# VPAC_DRU_UTC_VPAC0_DRU_MMR_CFG_DRU_DRU_CHATOMIC_DEBUG register map
Vendor: Texas Instruments
Peripheral module from a debugger description file (folder am62A).
Registers are 64-bit, read-only, reset 0x0 unless marked. A register's access mark holds for its fields unless they carry their own. Offsets are as the file gives them; lines under a group give offsets from that group; [hi:lo] are bit positions; {n}, {i} and the like mark numbered series; 'fields as' and 'values as' point back to an identical list; <NAME> marks a mode.

## VPAC_DRU_UTC_VPAC0_DRU_MMR_CFG_DRU_DRU_CHATOMIC_DEBUG
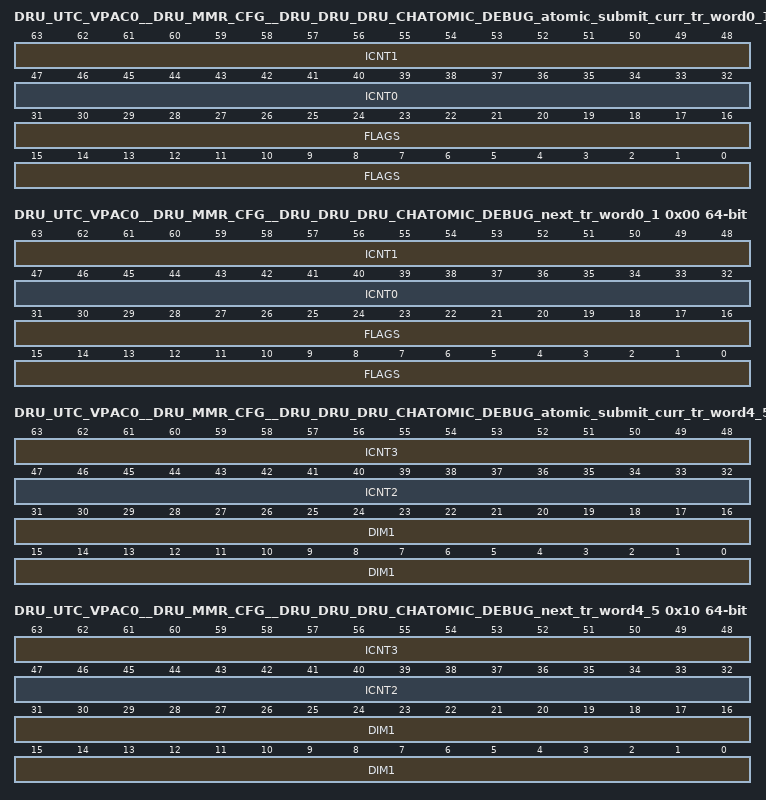
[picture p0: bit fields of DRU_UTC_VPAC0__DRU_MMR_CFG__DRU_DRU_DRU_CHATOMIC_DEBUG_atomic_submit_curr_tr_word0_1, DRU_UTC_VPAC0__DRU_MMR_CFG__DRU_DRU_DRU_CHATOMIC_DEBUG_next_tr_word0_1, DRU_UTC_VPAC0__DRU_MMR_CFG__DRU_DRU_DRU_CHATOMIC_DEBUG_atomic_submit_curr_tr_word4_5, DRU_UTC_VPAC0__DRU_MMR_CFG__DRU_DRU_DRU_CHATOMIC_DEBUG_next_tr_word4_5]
0x00 DRU_UTC_VPAC0__DRU_MMR_CFG__DRU_DRU_DRU_CHATOMIC_DEBUG_atomic_submit_curr_tr_word0_1
  [63:48] ICNT1 — Lines in a transfer
  [47:32] ICNT0 — Bytes in a transfer
  [31:0] FLAGS — Flags for the operation and type of descriptor
0x00 DRU_UTC_VPAC0__DRU_MMR_CFG__DRU_DRU_DRU_CHATOMIC_DEBUG_next_tr_word0_1
  fields as DRU_UTC_VPAC0__DRU_MMR_CFG__DRU_DRU_DRU_CHATOMIC_DEBUG_atomic_submit_curr_tr_word0_1
0x08 DRU_UTC_VPAC0__DRU_MMR_CFG__DRU_DRU_DRU_CHATOMIC_DEBUG_atomic_submit_curr_tr_word2_3
  [47:0] SRC_ADDR — Source transfer address virtual or physical allowed
0x08 DRU_UTC_VPAC0__DRU_MMR_CFG__DRU_DRU_DRU_CHATOMIC_DEBUG_next_tr_word2_3
  fields as DRU_UTC_VPAC0__DRU_MMR_CFG__DRU_DRU_DRU_CHATOMIC_DEBUG_atomic_submit_curr_tr_word2_3
0x10 DRU_UTC_VPAC0__DRU_MMR_CFG__DRU_DRU_DRU_CHATOMIC_DEBUG_atomic_submit_curr_tr_word4_5
  [63:48] ICNT3 — The size of the 4th loop in the TR transfer
  [47:32] ICNT2 — The size of the 3rd loop in the TR transfer
  [31:0] DIM1 — The first dimension width of the source data
0x10 DRU_UTC_VPAC0__DRU_MMR_CFG__DRU_DRU_DRU_CHATOMIC_DEBUG_next_tr_word4_5
  fields as DRU_UTC_VPAC0__DRU_MMR_CFG__DRU_DRU_DRU_CHATOMIC_DEBUG_atomic_submit_curr_tr_word4_5
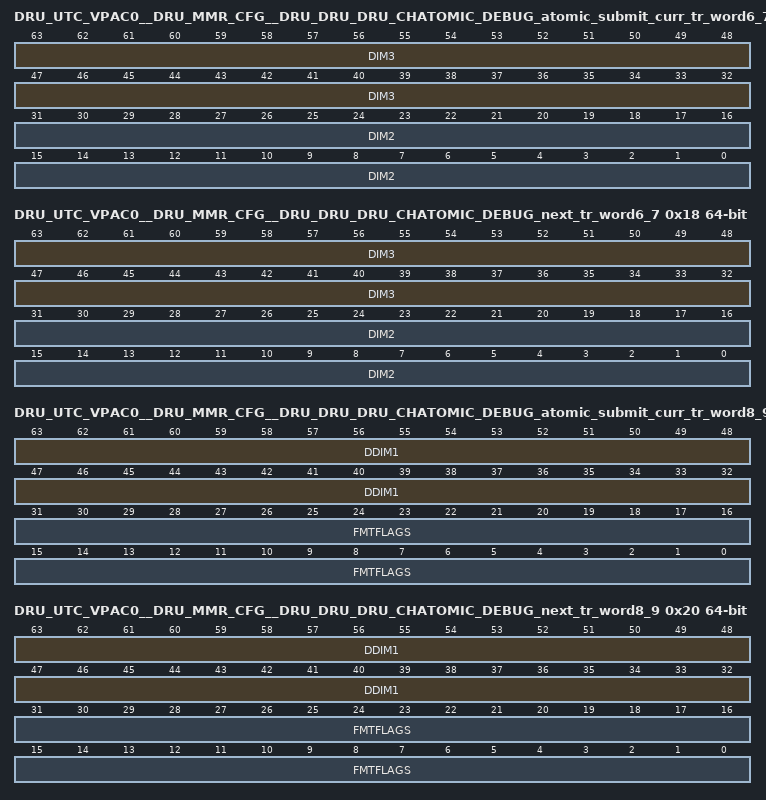
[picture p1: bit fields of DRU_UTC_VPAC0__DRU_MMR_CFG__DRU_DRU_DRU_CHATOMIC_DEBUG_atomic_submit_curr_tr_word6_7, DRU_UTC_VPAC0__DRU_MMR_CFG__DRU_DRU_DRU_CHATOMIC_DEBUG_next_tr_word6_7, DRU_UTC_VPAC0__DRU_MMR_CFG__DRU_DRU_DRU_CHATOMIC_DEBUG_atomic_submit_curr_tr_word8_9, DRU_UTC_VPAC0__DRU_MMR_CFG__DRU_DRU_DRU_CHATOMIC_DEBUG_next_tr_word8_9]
0x18 DRU_UTC_VPAC0__DRU_MMR_CFG__DRU_DRU_DRU_CHATOMIC_DEBUG_atomic_submit_curr_tr_word6_7
  [63:32] DIM3 — The third dimension width of the source data
  [31:0] DIM2 — The second dimension width of the source data
0x18 DRU_UTC_VPAC0__DRU_MMR_CFG__DRU_DRU_DRU_CHATOMIC_DEBUG_next_tr_word6_7
  fields as DRU_UTC_VPAC0__DRU_MMR_CFG__DRU_DRU_DRU_CHATOMIC_DEBUG_atomic_submit_curr_tr_word6_7
0x20 DRU_UTC_VPAC0__DRU_MMR_CFG__DRU_DRU_DRU_CHATOMIC_DEBUG_atomic_submit_curr_tr_word8_9
  [63:32] DDIM1 — The first dimension width of the destination data
  [31:0] FMTFLAGS — The data formatting flags to be used for the TR
0x20 DRU_UTC_VPAC0__DRU_MMR_CFG__DRU_DRU_DRU_CHATOMIC_DEBUG_next_tr_word8_9
  fields as DRU_UTC_VPAC0__DRU_MMR_CFG__DRU_DRU_DRU_CHATOMIC_DEBUG_atomic_submit_curr_tr_word8_9
0x28 DRU_UTC_VPAC0__DRU_MMR_CFG__DRU_DRU_DRU_CHATOMIC_DEBUG_atomic_submit_curr_tr_word10_11
  [47:0] DADDR — Destination transfer address virtual or physical allowed
0x28 DRU_UTC_VPAC0__DRU_MMR_CFG__DRU_DRU_DRU_CHATOMIC_DEBUG_next_tr_word10_11
  fields as DRU_UTC_VPAC0__DRU_MMR_CFG__DRU_DRU_DRU_CHATOMIC_DEBUG_atomic_submit_curr_tr_word10_11
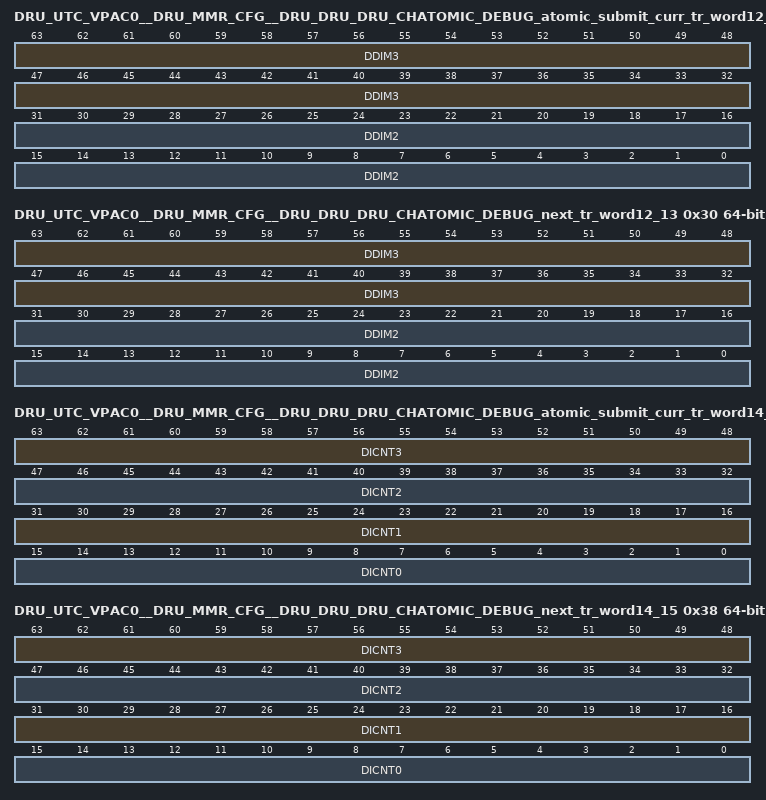
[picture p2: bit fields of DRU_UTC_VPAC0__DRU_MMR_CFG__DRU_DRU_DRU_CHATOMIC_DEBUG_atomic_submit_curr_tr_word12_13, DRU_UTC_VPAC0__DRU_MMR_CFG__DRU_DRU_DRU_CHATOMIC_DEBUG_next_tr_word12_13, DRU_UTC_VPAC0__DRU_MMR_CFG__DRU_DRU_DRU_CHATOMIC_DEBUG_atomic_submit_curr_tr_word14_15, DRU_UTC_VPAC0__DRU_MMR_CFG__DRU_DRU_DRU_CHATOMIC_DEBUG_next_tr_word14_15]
0x30 DRU_UTC_VPAC0__DRU_MMR_CFG__DRU_DRU_DRU_CHATOMIC_DEBUG_atomic_submit_curr_tr_word12_13
  [63:32] DDIM3 — The third dimension width of the destination data
  [31:0] DDIM2 — The second dimension width of the destination data
0x30 DRU_UTC_VPAC0__DRU_MMR_CFG__DRU_DRU_DRU_CHATOMIC_DEBUG_next_tr_word12_13
  fields as DRU_UTC_VPAC0__DRU_MMR_CFG__DRU_DRU_DRU_CHATOMIC_DEBUG_atomic_submit_curr_tr_word12_13
0x38 DRU_UTC_VPAC0__DRU_MMR_CFG__DRU_DRU_DRU_CHATOMIC_DEBUG_atomic_submit_curr_tr_word14_15
  [63:48] DICNT3 — The fourth count of the destination if different than the source
  [47:32] DICNT2 — The third count of the destination if different than the source
  [31:16] DICNT1 — The second innermost count of the destination if different than the source
  [15:0] DICNT0 — The innermost count of the destination if different than the source
0x38 DRU_UTC_VPAC0__DRU_MMR_CFG__DRU_DRU_DRU_CHATOMIC_DEBUG_next_tr_word14_15
  fields as DRU_UTC_VPAC0__DRU_MMR_CFG__DRU_DRU_DRU_CHATOMIC_DEBUG_atomic_submit_curr_tr_word14_15
